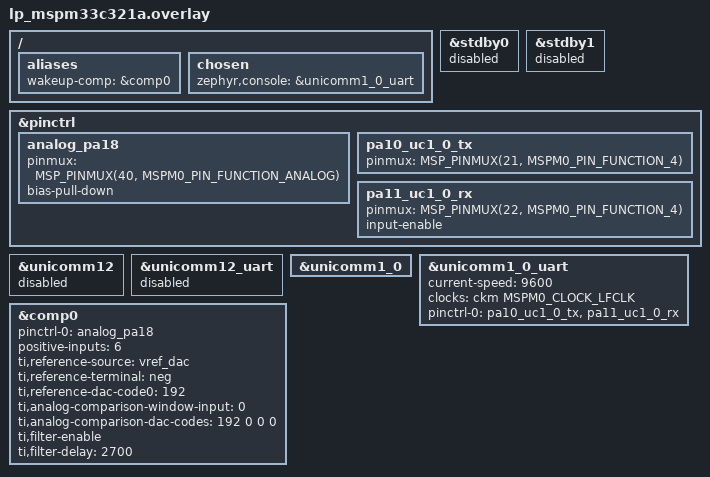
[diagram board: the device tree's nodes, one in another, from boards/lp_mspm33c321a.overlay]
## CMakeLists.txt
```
# SPDX-FileCopyrightText: 2026 Texas Instruments Incorporated
# SPDX-License-Identifier: LicenseRef-TI-TFL

cmake_minimum_required(VERSION 3.28.0)
find_package(Zephyr REQUIRED HINTS $ENV{ZEPHYR_BASE})

project(comp_analog_wakeup)

target_sources(app PRIVATE src/main.c)
```

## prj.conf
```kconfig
CONFIG_PM=y
CONFIG_COMPARATOR=y
CONFIG_REGULATOR=y
```

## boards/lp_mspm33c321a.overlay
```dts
/*
 * SPDX-FileCopyrightText: 2026 Texas Instruments Incorporated
 * SPDX-License-Identifier: LicenseRef-TI-TFL
 */

/ {
	aliases {
		wakeup-comp = &comp0;
	};

	chosen {
		zephyr,console = &unicomm1_0_uart;
	};
};

/* disable standby modes to explicitly allow entering STOP mode */
&stdby0 {
	status = "disabled";
};

&stdby1 {
	status = "disabled";
};

&pinctrl {
	analog_pa18: analog_pa18 {
		pinmux = <MSP_PINMUX(40, MSPM0_PIN_FUNCTION_ANALOG)>;
		bias-pull-down;
	};
};

&unicomm12 {
	status = "disabled";
};

&unicomm12_uart {
	status = "disabled";
};

&unicomm1_0 {
	status = "okay";
};

&pinctrl {
	pa10_uc1_0_tx: pa10_uc1_0_tx {
		pinmux = <MSP_PINMUX(21, MSPM0_PIN_FUNCTION_4)>;
	};

	pa11_uc1_0_rx: pa11_uc1_0_rx {
		pinmux = <MSP_PINMUX(22, MSPM0_PIN_FUNCTION_4)>;
		input-enable;
	};
};

&unicomm1_0_uart {
	status = "okay";
	current-speed = <9600>;
	clocks = <&ckm MSPM0_CLOCK_LFCLK>;

	pinctrl-0 = <&pa10_uc1_0_tx &pa11_uc1_0_rx>;
	pinctrl-names = "default";
};

&comp0 {
	status = "okay";
	pinctrl-0 = <&analog_pa18>;
	pinctrl-names = "default";
	positive-inputs = <6>;
	ti,reference-source = "vref_dac";
	ti,reference-terminal = "neg";
	ti,reference-dac-code0 = <192>;
	ti,analog-comparison-window-input = <0>;
	ti,analog-comparison-dac-codes = <192 0 0 0>;
	ti,filter-enable;
	ti,filter-delay = <2700>;
};
```

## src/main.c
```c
/*
 * SPDX-FileCopyrightText: 2026 Texas Instruments Incorporated
 * SPDX-License-Identifier: LicenseRef-TI-TFL
 */

#include <zephyr/device.h>
#include <zephyr/devicetree.h>
#include <zephyr/drivers/comparator.h>
#include <zephyr/kernel.h>
#include <zephyr/logging/log.h>

static void comparator_wakeup_cb(const struct device *dev, void *user_data)
{
	static uint32_t wake_count = 0;

	ARG_UNUSED(dev);
	ARG_UNUSED(user_data);

	printf("woke up (count=%u)\n", ++wake_count);
}

int main(void)
{
	const struct device *dev = DEVICE_DT_GET(DT_ALIAS(wakeup_comp));
	int ret = 0;

	if (!device_is_ready(dev)) {
		printf("comparator device not ready\n");
		return 0;
	}

	ret = comparator_set_trigger_callback(dev, comparator_wakeup_cb, NULL);
	if (ret < 0) {
		printf("failed to set trigger callback (%d)\n", ret);
		return 0;
	}

	ret = comparator_set_trigger(dev, COMPARATOR_TRIGGER_RISING_EDGE);
	if (ret < 0) {
		printf("failed to enable comparator trigger (%d)\n", ret);
		return 0;
	}

	return 0;
}
```
